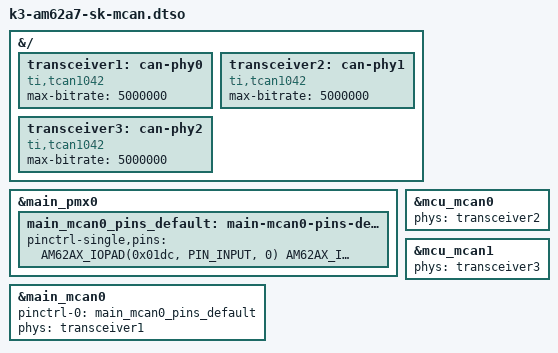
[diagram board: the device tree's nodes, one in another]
// SPDX-License-Identifier: GPL-2.0
/**
 * DT overlay to enable MCAN on AM62A7-SK
 *
 * Copyright (C) 2023 Texas Instruments Incorporated - https://www.ti.com/
 */

/dts-v1/;
/plugin/;

#include "k3-pinctrl.h"

&{/} {
	transceiver1: can-phy0 {
		compatible = "ti,tcan1042";
		#phy-cells = <0>;
		max-bitrate = <5000000>;
	};

	transceiver2: can-phy1 {
		compatible = "ti,tcan1042";
		#phy-cells = <0>;
		max-bitrate = <5000000>;
	};

	transceiver3: can-phy2 {
		compatible = "ti,tcan1042";
		#phy-cells = <0>;
		max-bitrate = <5000000>;
	};
};

&main_pmx0 {
	main_mcan0_pins_default: main-mcan0-pins-default {
		pinctrl-single,pins = <
			AM62AX_IOPAD(0x01dc, PIN_INPUT, 0) /* (C18) MCAN0_RX */
			AM62AX_IOPAD(0x01d8, PIN_OUTPUT, 0) /* (B17) MCAN0_TX */
		>;
	};
};

&main_mcan0 {
	/* J3: RX=P8/TX=P10 */
	pinctrl-names = "default";
	pinctrl-0 = <&main_mcan0_pins_default>;
	phys = <&transceiver1>;
	status = "okay";
};

&mcu_mcan0 {
	/* J10: RX=P22/TX=P16 */
	phys = <&transceiver2>;
	status = "okay";
};

&mcu_mcan1 {
	/* J10: RX=P11/TX=P10 */
	phys = <&transceiver3>;
	status = "okay";
};
